# PIC32CX5109BZ36048_SL3 register map
Vendor: Microchip Technology; Series: PIC32CXBZ36; File version: 0
CPU: CM4 r0p1, little endian, MPU, FPU, 3 interrupt priority bits, 43 interrupts
Registers are 32-bit, read-write, reset 0x0 unless marked. A register's access mark holds for its fields unless they carry their own. Offsets are from the block's base; [hi:lo] are bit positions; {n}, {i} and the like mark numbered series.

## EFUSE
Base 0x00000000
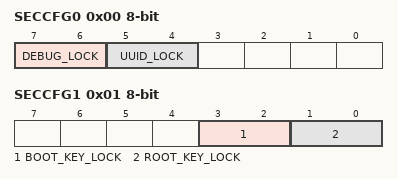
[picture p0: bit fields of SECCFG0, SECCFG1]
0x00 SECCFG0 8-bit — Secure Configuration
  [7:6] DEBUG_LOCK — Lock bits for debug/programming
    0=DEBUG_NOT_LCK_0 (Debug is not locked); 1=DEBUG_LCK_1 (Debug is locked); 2=DEBUG_LCK_2 (Debug is locked); 3=DEBUG_LCK_3 (Debug is locked)
  [5:4] UUID_LOCK — Programming lock bits for Unique ID fuses
    0=UUID_NOT_LCK_0 (Unique ID is not locked); 1=UUID_LCK_NO_PROG_1 (Unique ID is locked and cannot be programmed); 2=UUID_LCK_NO_PROG_2 (Unique ID is locked and cannot be programmed); 3=UUID_LCK_NO_PROG_3 (Unique ID is locked and cannot be programmed)
0x01 SECCFG1 8-bit — Secure Configuration
  [3:2] BOOT_KEY_LOCK — Lock bits for Secure Boot/OTA Key
    0=BOOT_KEY_NOT_LCK_0 (Secure boot key is not locked); 1=BOOT_KEY_LCK_1 (Secure boot key is locked and cannot be programmed); 2=BOOT_KEY_LCK_2 (Secure boot key is locked and cannot be programmed); 3=BOOT_KEY_LCK_3 (Secure boot key is locked and cannot be programmed)
  [1:0] ROOT_KEY_LOCK — Lock bits for storage root Key
    0=ROOT_KEY_NOT_LCK_0 (Storage root key is not locked); 1=ROOT_KEY_LCK_1 (Storage root key is locked and cannot be programmed); 2=ROOT_KEY_LCK_2 (Storage root key is locked and cannot be programmed); 3=ROOT_KEY_LCK_3 (Storage root key is locked and cannot be programmed)
0x02 SECCFG2 8-bit — Secure Configuration
  [0] ADD_BOOT_KEY — Additional boot Key bit
{0x4+i} ANTIROLLBACKCOUNTER[{i}] (i=0..31) 8-bit
  [7:0] ANTIROLLBACKCOUNTER — Anti rollback counter bits
{0x24+i} LIFECYCLECOUNTER[{i}] (i=0..1) 8-bit
  [7:0] LIFECYCLECOUNTER — Life cycle counter bits
{0x26+i} SECUREBOOTKEY[{i}] (i=0..47) 8-bit
  [7:0] SECUREBOOTKEY — Secure boot key bits
{0x1D8+i} UUID[{i}] (i=0..15) 8-bit — Unique ID
  [7:0] UUID — Unique ID bits

## ETM — Embedded Trace Macrocell
Base 0xE0041000
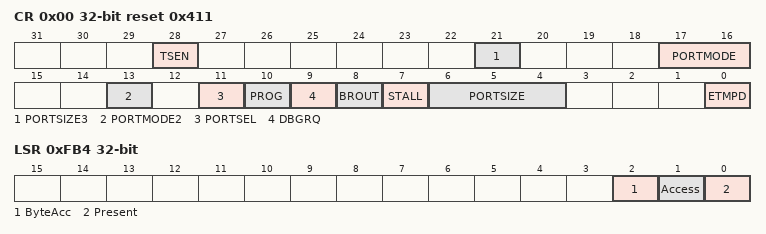
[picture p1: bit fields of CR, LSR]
0x00 CR reset 0x411 — ETM Main Control Register
  [28] TSEN — TimeStamp Enable
  [21] PORTSIZE3 — Port Size bit 3
  [17:16] PORTMODE — Port Mode bits 1:0
  [13] PORTMODE2 — Port Mode bit 2
  [11] PORTSEL — ETM Port Select
  [10] PROG — ETM Programming
  [9] DBGRQ — Debug Request Control
  [8] BROUT — Branch Output
  [7] STALL — Stall Processor
  [6:4] PORTSIZE — Port Size bits 2:0
  [0] ETMPD — ETM Power Down
0x04 CCR ro reset 0x8C802000 — ETM Configuration Code Register
0x08 TRIGGER — ETM Trigger Event Register
0x10 SR — ETM Status Register
0x14 SCR ro reset 0x20D09 — ETM System Configuration Register
0x20 TEEVR — ETM TraceEnable Event Register
0x24 TECR1 — ETM TraceEnable Control 1 Register
0x28 FFLR — ETM FIFO Full Level Register
0x140 CNTRLDVR1 — ETM Free-running Counter Reload Value
0x1E0 SYNCFR ro reset 0x400 — ETM Synchronization Frequency Register
0x1E4 IDR ro reset 0x4114F250 — ETM ID Register
0x1E8 CCER ro reset 0x18541800 — ETM Configuration Code Extension Register
0x1F0 TESSEICR — ETM TraceEnable Start/Stop EmbeddedICE Control Register
0x1F8 TSEVT — ETM TimeStamp Event Register
0x200 TRACEIDR — ETM CoreSight Trace ID Register
0x208 IDR2 ro — ETM ID Register 2
0x314 PDSR ro reset 0x1 — ETM Device Power-Down Status Register
0xEE0 ITMISCIN ro — ETM Integration Test Miscellaneous Inputs
0xEE8 ITTRIGOUT wo — ETM Integration Test Trigger Out
0xEF0 ITATBCTR2 ro — ETM Integration Test ATB Control 2
0xEF8 ITATBCTR0 wo — ETM Integration Test ATB Control 0
0xF00 ITCTRL — ETM Integration Mode Control Register
  [0] INTEGRATION
0xFA0 CLAIMSET write-1-sets — ETM Claim Tag Set Register
0xFA4 CLAIMCLR write-1-clears — ETM Claim Tag Clear Register
0xFB0 LAR wo — ETM Lock Access Register
0xFB4 LSR ro — ETM Lock Status Register
  [2] ByteAcc, [1] Access, [0] Present
0xFB8 AUTHSTATUS ro — ETM Authentication Status Register
0xFCC DEVTYPE ro reset 0x13 — ETM CoreSight Device Type Register
0xFD0 PIDR4 ro reset 0x4 — ETM Peripheral Identification Register #4
{0xFC0+4i} PIDR{i} ro (i=5..7) — ETM Peripheral Identification Register #{i}
0xFE0 PIDR0 ro reset 0x25 — ETM Peripheral Identification Register #0
0xFE4 PIDR1 ro reset 0xB9 — ETM Peripheral Identification Register #1
0xFE8 PIDR2 ro reset 0xB — ETM Peripheral Identification Register #2
0xFEC PIDR3 ro — ETM Peripheral Identification Register #3
0xFF0 CIDR0 ro reset 0xD — ETM Component Identification Register #0
0xFF4 CIDR1 ro reset 0x90 — ETM Component Identification Register #1
0xFF8 CIDR2 ro reset 0x5 — ETM Component Identification Register #2
0xFFC CIDR3 ro reset 0xB1 — ETM Component Identification Register #3
